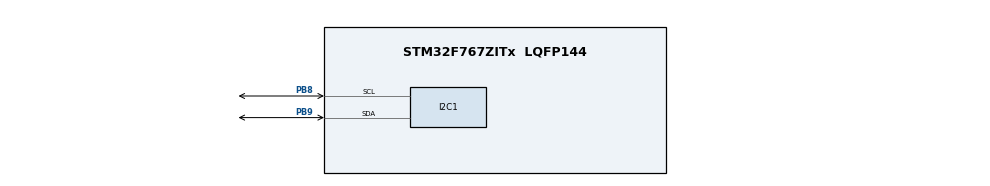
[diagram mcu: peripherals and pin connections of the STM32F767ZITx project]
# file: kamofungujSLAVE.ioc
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CORTEX_M7.default_mode_Activation=1
Dma.I2C1_RX.1.Direction=DMA_PERIPH_TO_MEMORY
Dma.I2C1_RX.1.FIFOMode=DMA_FIFOMODE_DISABLE
Dma.I2C1_RX.1.Instance=DMA1_Stream0
Dma.I2C1_RX.1.MemDataAlignment=DMA_MDATAALIGN_BYTE
Dma.I2C1_RX.1.MemInc=DMA_MINC_ENABLE
Dma.I2C1_RX.1.Mode=DMA_NORMAL
Dma.I2C1_RX.1.PeriphDataAlignment=DMA_PDATAALIGN_BYTE
Dma.I2C1_RX.1.PeriphInc=DMA_PINC_DISABLE
Dma.I2C1_RX.1.Priority=DMA_PRIORITY_LOW
Dma.I2C1_TX.0.Direction=DMA_MEMORY_TO_PERIPH
Dma.I2C1_TX.0.FIFOMode=DMA_FIFOMODE_DISABLE
Dma.I2C1_TX.0.Instance=DMA1_Stream6
Dma.I2C1_TX.0.MemDataAlignment=DMA_MDATAALIGN_BYTE
Dma.I2C1_TX.0.MemInc=DMA_MINC_ENABLE
Dma.I2C1_TX.0.Mode=DMA_NORMAL
Dma.I2C1_TX.0.PeriphDataAlignment=DMA_PDATAALIGN_BYTE
Dma.I2C1_TX.0.PeriphInc=DMA_PINC_DISABLE
Dma.I2C1_TX.0.Priority=DMA_PRIORITY_LOW
Dma.Request0=I2C1_TX
Dma.Request1=I2C1_RX
Mcu.Family=STM32F7
Mcu.Name=STM32F767ZITx
Mcu.Package=LQFP144
NVIC.DMA1_Stream0_IRQn=true\:0\:0\:false\:false\:true\:false\:true\:true
NVIC.DMA1_Stream6_IRQn=true\:0\:0\:false\:false\:true\:false\:true\:true
NVIC.I2C1_ER_IRQn=true\:0\:0\:false\:false\:true\:true\:true\:true
NVIC.I2C1_EV_IRQn=true\:0\:0\:false\:false\:true\:true\:true\:true
NVIC.PriorityGroup=NVIC_PRIORITYGROUP_4
PB8.GPIO_Pu=GPIO_PULLUP
PB8.Mode=I2C
PB8.Signal=I2C1_SCL
PB9.GPIO_Pu=GPIO_PULLUP
PB9.Mode=I2C
PB9.Signal=I2C1_SDA
ProjectManager.HeapSize=0x200
ProjectManager.StackSize=0x400
ProjectManager.TargetToolchain=STM32CubeIDE
RCC.HSE_VALUE=25000000
RCC.HSI_VALUE=16000000
RCC.LSE_VALUE=32768
RCC.USBFreq_Value=96000000
RCC.VCOOutputFreq_Value=192000000
board=custom

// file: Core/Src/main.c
/* USER CODE BEGIN Header */
/**
  ******************************************************************************
  * @file           : main.c
  * @brief          : Main program body
  ******************************************************************************
  * @attention
  *
  * Copyright (c) 2026 STMicroelectronics.
  * All rights reserved.
  *
  * This software is licensed under terms that can be found in the LICENSE file
  * in the root directory of this software component.
  * If no LICENSE file comes with this software, it is provided AS-IS.
  *
  ******************************************************************************
  */
/* USER CODE END Header */
#include "main.h"

I2C_HandleTypeDef hi2c1;
DMA_HandleTypeDef hdma_i2c1_tx;
DMA_HandleTypeDef hdma_i2c1_rx;

/* USER CODE BEGIN PV */
uint8_t TX_Buffer[] = "A";

/* USER CODE END PV */

void SystemClock_Config(void);
static void MPU_Config(void);
static void MX_GPIO_Init(void);
static void MX_DMA_Init(void);
static void MX_I2C1_Init(void);

int main(void)
{

  /* MPU Configuration--------------------------------------------------------*/
  MPU_Config();

  /* MCU Configuration--------------------------------------------------------*/

  /* Reset of all peripherals, Initializes the Flash interface and the Systick. */
  HAL_Init();

  /* Configure the system clock */
  SystemClock_Config();

  /* Initialize all configured peripherals */
  MX_GPIO_Init();
  MX_DMA_Init();
  MX_I2C1_Init();

  /* Infinite loop */
  while (1)
  {
	  HAL_StatusTypeDef ret;

	  ret = HAL_I2C_Master_Transmit(&hi2c1,0x14 << 1, TX_Buffer, 1, 1000);
	  uint32_t err = HAL_I2C_GetError(&hi2c1);
	  HAL_Delay(100);

  }
}

void SystemClock_Config(void)
{
  RCC_OscInitTypeDef RCC_OscInitStruct = {0};
  RCC_ClkInitTypeDef RCC_ClkInitStruct = {0};

  /** Configure the main internal regulator output voltage
  */
  __HAL_RCC_PWR_CLK_ENABLE();
  __HAL_PWR_VOLTAGESCALING_CONFIG(PWR_REGULATOR_VOLTAGE_SCALE3);

  /** Initializes the RCC Oscillators according to the specified parameters
  * in the RCC_OscInitTypeDef structure.
  */
  RCC_OscInitStruct.OscillatorType = RCC_OSCILLATORTYPE_HSI;
  RCC_OscInitStruct.HSIState = RCC_HSI_ON;
  RCC_OscInitStruct.HSICalibrationValue = RCC_HSICALIBRATION_DEFAULT;
  RCC_OscInitStruct.PLL.PLLState = RCC_PLL_NONE;
  if (HAL_RCC_OscConfig(&RCC_OscInitStruct) != HAL_OK)
  {
    Error_Handler();
  }

  /** Initializes the CPU, AHB and APB buses clocks
  */
  RCC_ClkInitStruct.ClockType = RCC_CLOCKTYPE_HCLK|RCC_CLOCKTYPE_SYSCLK
                              |RCC_CLOCKTYPE_PCLK1|RCC_CLOCKTYPE_PCLK2;
  RCC_ClkInitStruct.SYSCLKSource = RCC_SYSCLKSOURCE_HSI;
  RCC_ClkInitStruct.AHBCLKDivider = RCC_SYSCLK_DIV1;
  RCC_ClkInitStruct.APB1CLKDivider = RCC_HCLK_DIV1;
  RCC_ClkInitStruct.APB2CLKDivider = RCC_HCLK_DIV1;

  if (HAL_RCC_ClockConfig(&RCC_ClkInitStruct, FLASH_LATENCY_0) != HAL_OK)
  {
    Error_Handler();
  }
}

static void MX_I2C1_Init(void)
{

  hi2c1.Instance = I2C1;
  hi2c1.Init.Timing = 0x00303D5B;
  hi2c1.Init.OwnAddress1 = 0;
  hi2c1.Init.AddressingMode = I2C_ADDRESSINGMODE_7BIT;
  hi2c1.Init.DualAddressMode = I2C_DUALADDRESS_DISABLE;
  hi2c1.Init.OwnAddress2 = 0;
  hi2c1.Init.OwnAddress2Masks = I2C_OA2_NOMASK;
  hi2c1.Init.GeneralCallMode = I2C_GENERALCALL_DISABLE;
  hi2c1.Init.NoStretchMode = I2C_NOSTRETCH_DISABLE;
  if (HAL_I2C_Init(&hi2c1) != HAL_OK)
  {
    Error_Handler();
  }

  /** Configure Analogue filter
  */
  if (HAL_I2CEx_ConfigAnalogFilter(&hi2c1, I2C_ANALOGFILTER_ENABLE) != HAL_OK)
  {
    Error_Handler();
  }

  /** Configure Digital filter
  */
  if (HAL_I2CEx_ConfigDigitalFilter(&hi2c1, 0) != HAL_OK)
  {
    Error_Handler();
  }

}

static void MX_DMA_Init(void)
{

  /* DMA controller clock enable */
  __HAL_RCC_DMA1_CLK_ENABLE();

  /* DMA interrupt init */
  /* DMA1_Stream0_IRQn interrupt configuration */
  HAL_NVIC_SetPriority(DMA1_Stream0_IRQn, 0, 0);
  HAL_NVIC_EnableIRQ(DMA1_Stream0_IRQn);
  /* DMA1_Stream6_IRQn interrupt configuration */
  HAL_NVIC_SetPriority(DMA1_Stream6_IRQn, 0, 0);
  HAL_NVIC_EnableIRQ(DMA1_Stream6_IRQn);

}

static void MX_GPIO_Init(void)
{

  /* GPIO Ports Clock Enable */
  __HAL_RCC_GPIOB_CLK_ENABLE();

}

 /* MPU Configuration */

void MPU_Config(void)
{
  MPU_Region_InitTypeDef MPU_InitStruct = {0};

  /* Disables the MPU */
  HAL_MPU_Disable();

  /** Initializes and configures the Region and the memory to be protected
  */
  MPU_InitStruct.Enable = MPU_REGION_ENABLE;
  MPU_InitStruct.Number = MPU_REGION_NUMBER0;
  MPU_InitStruct.BaseAddress = 0x0;
  MPU_InitStruct.Size = MPU_REGION_SIZE_4GB;
  MPU_InitStruct.SubRegionDisable = 0x87;
  MPU_InitStruct.TypeExtField = MPU_TEX_LEVEL0;
  MPU_InitStruct.AccessPermission = MPU_REGION_NO_ACCESS;
  MPU_InitStruct.DisableExec = MPU_INSTRUCTION_ACCESS_DISABLE;
  MPU_InitStruct.IsShareable = MPU_ACCESS_SHAREABLE;
  MPU_InitStruct.IsCacheable = MPU_ACCESS_NOT_CACHEABLE;
  MPU_InitStruct.IsBufferable = MPU_ACCESS_NOT_BUFFERABLE;

  HAL_MPU_ConfigRegion(&MPU_InitStruct);
  /* Enables the MPU */
  HAL_MPU_Enable(MPU_PRIVILEGED_DEFAULT);

}

void Error_Handler(void)
{
  __disable_irq();
  while (1)
  {
  }
}
